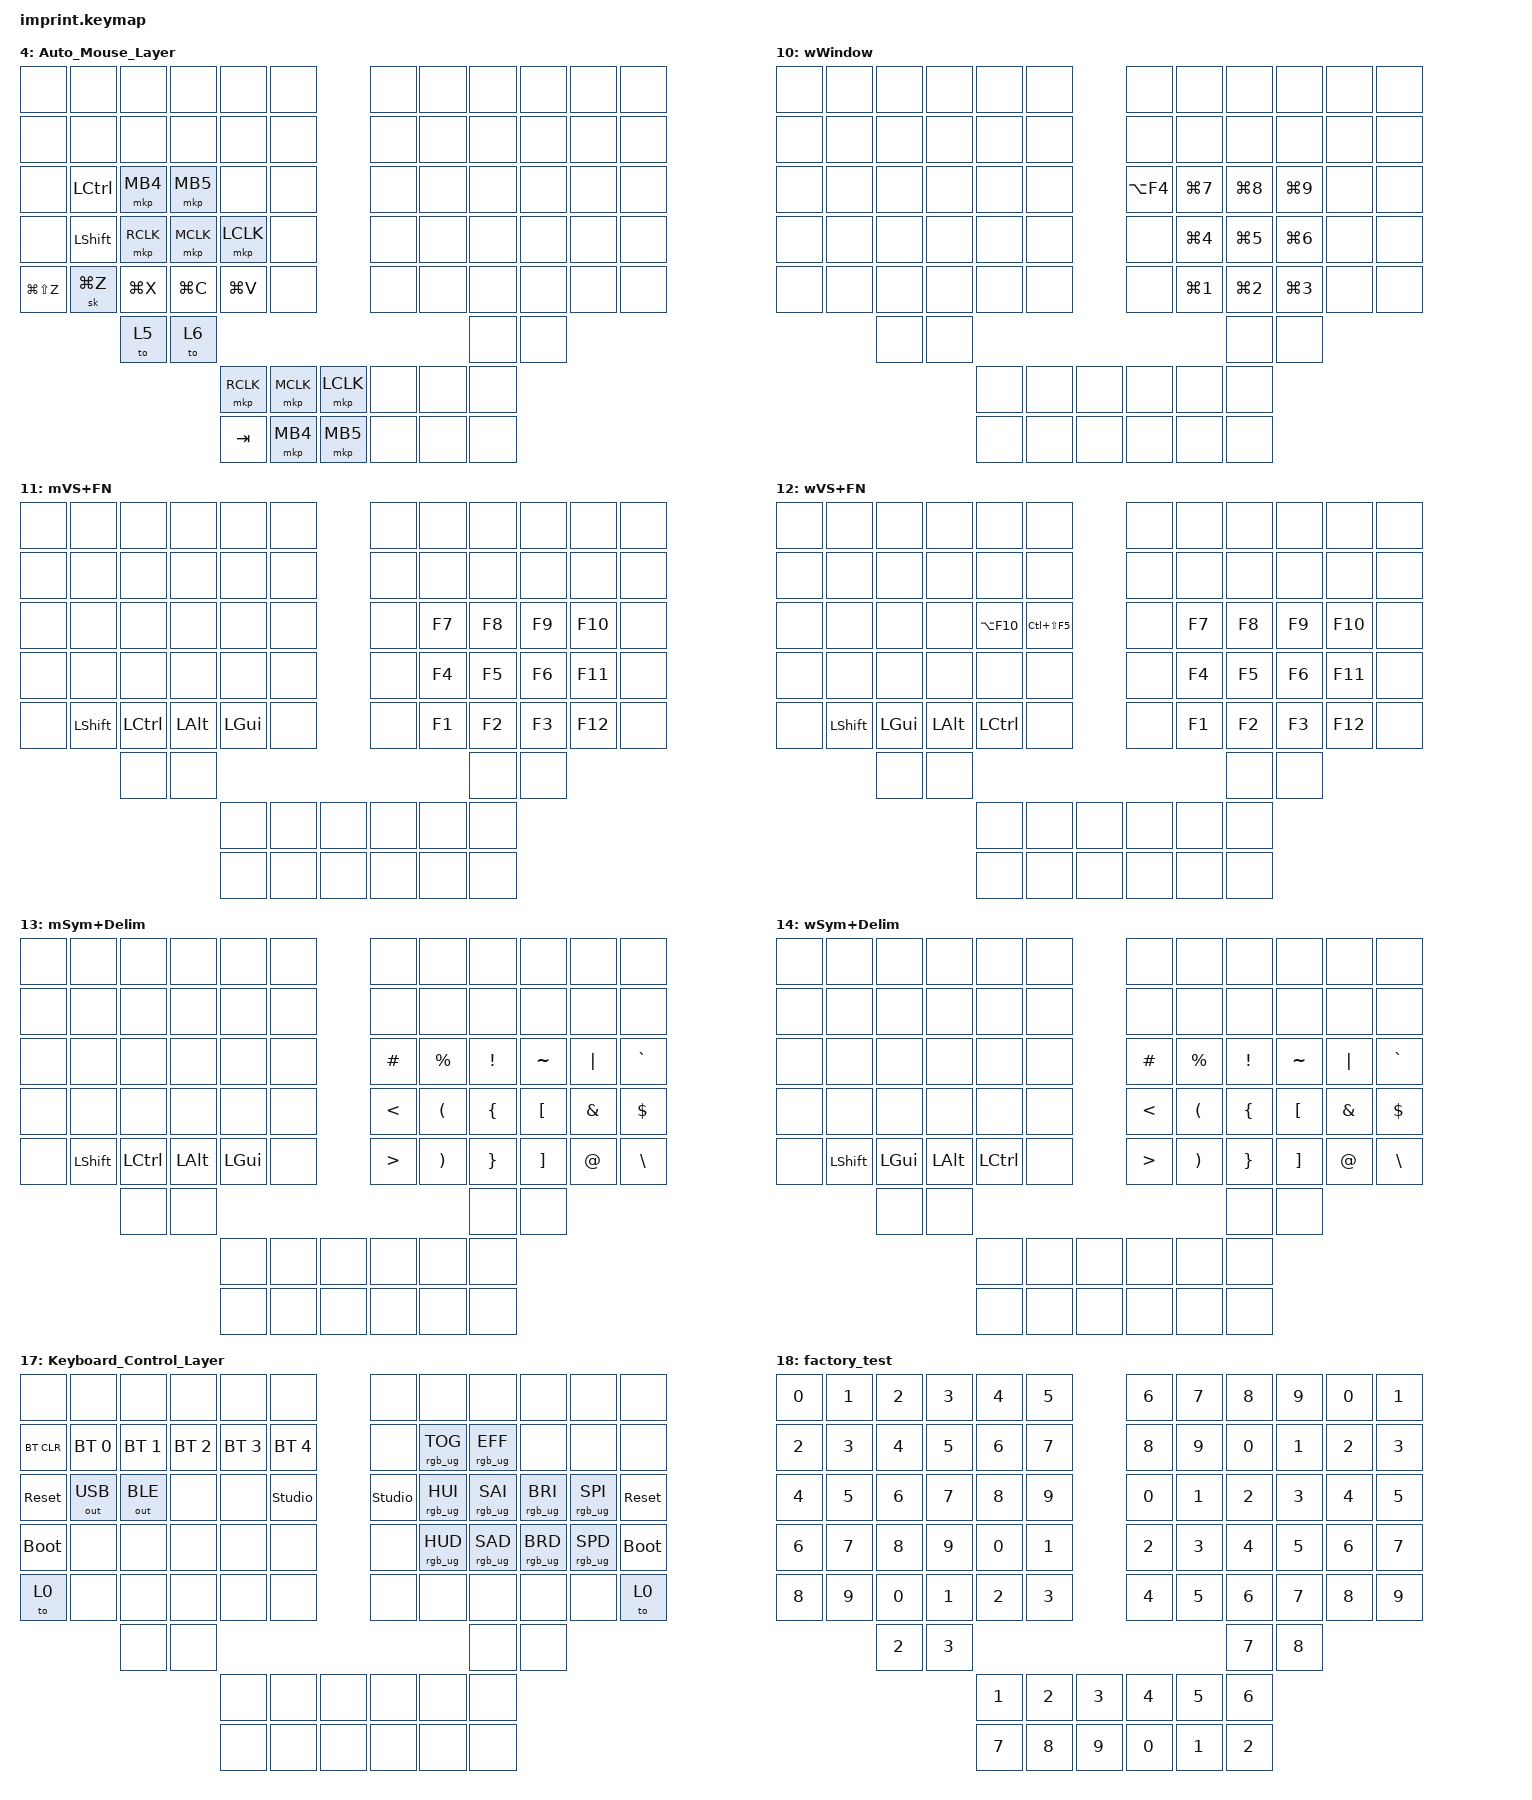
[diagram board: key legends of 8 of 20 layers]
#include <input/processors.dtsi>
#include <dt-bindings/zmk/input_transform.h>
#include <behaviors.dtsi>
#include <dt-bindings/zmk/bt.h>
#include <dt-bindings/zmk/keys.h>
#include <dt-bindings/zmk/outputs.h>
#include <dt-bindings/zmk/pointing.h>
#include <dt-bindings/zmk/rgb.h>

&mt {
    tapping-term-ms = <280>;
    quick-tap-ms = <175>;
    require-prior-idle-ms = <125>;
    flavor = "balanced";
};

&sk {
    quick-release;
    lazy;
};

/ {
    chosen { zmk,matrix-transform = &imprint_function_row; };

    combos {
        compatible = "zmk,combos";

        return {
            bindings = <&kp RET>;
            key-positions = <45 44 46>;
        };

        capsLock {
            bindings = <&kp CLCK>;
            key-positions = <56 57 51 50>;
        };

        tab {
            bindings = <&kp TAB>;
            key-positions = <43 44 45>;
        };

        backTab {
            bindings = <&kp LS(TAB)>;
            key-positions = <43 44 42>;
        };

        mHomeRowApp {
            bindings = <&kp LS(LA(LC(LG(F))))>;
            key-positions = <71 40>;
            layers = <0 2 7 9 11 13 15>;
        };

        lshift {
            bindings = <&kp LSHFT>;
            key-positions = <38 39>;
        };

        rshift {
            bindings = <&kp RSHIFT>;
            key-positions = <44 45>;
        };

        escape {
            bindings = <&kp ESCAPE>;
            key-positions = <43 44 45 46>;
        };

        mDelWord {
            bindings = <&kp LA(BACKSPACE)>;
            key-positions = <70 75>;
            layers = <0 2 7 9 11 13 15>;
        };

        StickyShift {
            bindings = <&sk LEFT_SHIFT>;
            key-positions = <71 74>;
        };

        To_MACOS {
            bindings = <&to_MAC_BASE>;
            key-positions = <36 37 38>;
        };

        to_mCSTR {
            bindings = <&to 2>;
            key-positions = <12 13 14>;
            layers = <0 2 7 9 11 13 15>;
        };

        to_SYS {
            bindings = <&to_SYS>;
            key-positions = <50 49 48>;
        };

        to_WINDOW {
            bindings = <&to_WINDOWS_BASE>;
            key-positions = <24 25 26>;
        };

        mLeaderKey {
            bindings = <&kp LS(LA(LC(RIGHT)))>;
            key-positions = <74 44>;
            layers = <0 2 7 9 11 13 15>;
        };

        caps_word {
            bindings = <&caps_word>;
            key-positions = <26 27 32 33>;
        };

        wDelWord {
            bindings = <&kp LC(BACKSPACE)>;
            key-positions = <75 70>;
        };

        to_wCSTR {
            bindings = <&to 3>;
            key-positions = <12 13 14>;
            layers = <1 3 8 10 12 14 16>;
        };

        goTo_MACOS {
            bindings = <&to_MACOS_OS>;
            key-positions = <13 22>;
        };

        goTo_WORK_WINDOW {
            bindings = <&to_WORK_WINDOW_OS>;
            key-positions = <17 18>;
        };

        sys_reset {
            bindings = <&sys_reset>;
            key-positions = <64 65 66>;
        };

        toggleRGB {
            bindings = <&rgb_ug RGB_TOG>;
            key-positions = <63 62>;
        };

        to_mGaming {
            bindings = <&to 19>;
            key-positions = <60 61 48 49>;
        };

        goTo_FUN_WINDOW {
            bindings = <&to_FUN_WINDOWS_OS>;
            key-positions = <16 19>;
        };

        goTo_IOS {
            bindings = <&to_IOS_OS>;
            key-positions = <14 21>;
        };

        goTo_IPADOS {
            bindings = <&to_IPADOS_OS>;
            key-positions = <15 20>;
        };
    };

    macros {
        wDelLine: wDelLine {
            compatible = "zmk,behavior-macro";
            #binding-cells = <0>;
            bindings = <&macro_tap>, <&kp END &kp LS(HOME) &kp BACKSPACE>;

            label = "WDELLINE";
        };

        mDelLine: mDelLine {
            compatible = "zmk,behavior-macro";
            #binding-cells = <0>;
            bindings = <&macro_tap>, <&kp LG(RIGHT) &kp LG(BACKSPACE)>;

            label = "MDELLINE";
        };

        wCtrlAltDel: wCtrlAltDel {
            compatible = "zmk,behavior-macro";
            #binding-cells = <0>;
            bindings = <&kp LA(LC(DEL))>;
            label = "WCTRLALTDEL";
        };

        to_MACOS_OS: toMACOS {
            compatible = "zmk,behavior-macro";
            #binding-cells = <0>;
            bindings = <&bt BT_SEL 0 &out OUT_BLE &to_MAC_BASE>;
            label = "TOMACOS";
        };

        to_WORK_WINDOW_OS: toWINDOW {
            compatible = "zmk,behavior-macro";
            #binding-cells = <0>;
            bindings = <&bt BT_SEL 4 &out OUT_BLE &to_WINDOWS_BASE>;
            label = "TOWINDOW";
        };

        calibrePressG: calibrePressG {
            compatible = "zmk,behavior-macro";
            #binding-cells = <0>;
            bindings =
                <&macro_wait_time 1>,
                <&kp LS(LA(LC(RIGHT))) &kp C>,
                <&macro_wait_time 100>,
                <&kp R &kp G>,
                <&macro_wait_time 1>,
                <&kp LS(LA(LC(RIGHT))) &kp O>;

            label = "CALIBREPRESSG";
        };

        to_SYS: to_SYS {
            compatible = "zmk,behavior-macro";
            #binding-cells = <0>;
            bindings = <&to 17 &rgb_ug RGB_COLOR_HSB(282,100,50)>;
            label = "TO_SYS";
        };

        to_WINDOWS_BASE: to_WINDOWS_BASE {
            compatible = "zmk,behavior-macro";
            #binding-cells = <0>;
            bindings = <&to 1 &rgb_ug RGB_COLOR_HSB(102,100,50)>;
            label = "TO_WINDOWS_BASE";
        };

        to_MAC_BASE: to_MAC_BASE {
            compatible = "zmk,behavior-macro";
            #binding-cells = <0>;
            bindings = <&to 0 &rgb_ug RGB_COLOR_HSB(21,100,50)>;
            label = "TO_MAC_BASE";
        };

        to_FUN_WINDOWS_OS: to_FUN_WINDOWS_OS {
            compatible = "zmk,behavior-macro";
            #binding-cells = <0>;
            bindings = <&bt BT_SEL 3 &out OUT_BLE &to_WINDOWS_BASE>;
            label = "TO_FUN_WINDOWS_OS";
        };

        to_IOS_OS: to_IOS {
            compatible = "zmk,behavior-macro";
            #binding-cells = <0>;
            bindings = <&bt BT_SEL 1 &out OUT_BLE &to_MAC_BASE>;
            label = "TO_IOS";
        };

        to_IPADOS_OS: to_IPADOS_OS {
            compatible = "zmk,behavior-macro";
            #binding-cells = <0>;
            bindings = <&bt BT_SEL 2 &out OUT_BLE &to_MAC_BASE>;
            label = "TO_IPADOS_OS";
        };

        mSwapLetters: swapLetters {
            compatible = "zmk,behavior-macro";
            #binding-cells = <0>;
            bindings = <&kp LS(RIGHT) &kp LG(X) &kp LEFT &kp LG(V)>;
            label = "SWAPLETTERS";
        };

        wSwapLetters: wSwapLetters {
            compatible = "zmk,behavior-macro";
            #binding-cells = <0>;
            bindings = <&kp LS(RIGHT) &kp LC(X) &kp LEFT &kp LC(V)>;
            label = "WSWAPLETTERS";
        };
    };

    keymap {
        compatible = "zmk,keymap";

        MAC_BASE {
            bindings = <
&none     &none             &none               &none           &none               &none                                                        &none                                &none                &none                &none                     &none                  &none
&none     &none             &none               &none           &none               &none                                                        &none                                &none                &none                &none                     &none                  &none
&kp ESC   &kp Q             &kp W               &kp E           &kp R               &kp T                                                        &kp Y                                &kp U                &kp I                &kp O                     &kp P                  &kp MINUS
&kp HASH  &kp A             &kp S               &kp D           &kp F               &kp G                                                        &kp H                                &kp J                &kp K                &kp L                     &kp SEMI               &kp SQT
&none     &mt LEFT_SHIFT Z  &mt LEFT_CONTROL X  &mt LEFT_ALT C  &mt LEFT_COMMAND V  &mt LG(LC(LS(LA(LEFT_COMMAND)))) B                           &mt RS(RA(RC(RG(RIGHT_COMMAND)))) N  &mt RIGHT_COMMAND M  &mt RIGHT_ALT COMMA  &mt RIGHT_CONTROL PERIOD  &mt RIGHT_SHIFT SLASH  &none
                            &to 5               &none                                                                                                                                                      &kp MINUS            &none
                                                                &lt 9 ESCAPE        &sk LEFT_SHIFT                      &kp LC(LS(LG(SPACE)))    &none                                &kp SPACE            &lt 11 DEL
                                                                &lt 15 TAB          &lt 7 E                             &kp RET                  &mSwapLetters                        &kp SPACE            &lt 13 BACKSPACE
            >;
        };

        WINDOW_BASE {
            bindings = <
&none    &none             &none           &none           &none               &none                                              &none                                &none                &none                &none                 &none                  &none
&none    &none             &none           &none           &none               &none                                              &none                                &none                &none                &none                 &none                  &none
&kp ESC  &kp Q             &kp W           &kp E           &kp R               &kp T                                              &kp Y                                &kp U                &kp I                &kp O                 &kp P                  &kp MINUS
&none    &kp A             &kp S           &kp D           &kp F               &kp G                                              &kp H                                &kp J                &kp K                &kp L                 &kp SEMI               &kp SQT
&none    &mt LEFT_SHIFT Z  &mt LEFT_GUI X  &mt LEFT_ALT C  &mt LEFT_CONTROL V  &mt LG(LC(LS(LA(LEFT_COMMAND)))) B                 &mt RS(RA(RC(RG(RIGHT_COMMAND)))) N  &mt RIGHT_CONTROL M  &mt RIGHT_ALT COMMA  &mt RIGHT_GUI PERIOD  &mt RIGHT_SHIFT SLASH  &none
                           &none           &to 6                                                                                                                                            &kp MINUS            &none
                                                           &lt 10 ESCAPE       &sk LEFT_SHIFT                      &kp LA(TAB)    &none                                &none                &lt 12 DEL
                                                           &lt 16 TAB          &lt 8 E                             &kp RET        &wSwapLetters                        &kp SPACE            &lt 14 BACKSPACE
            >;
        };

        mCSTR {
            bindings = <
&none     &none             &none               &none           &none               &none                                                                &none                                    &none                &none                &none                     &none              &none
&none     &none             &none               &none           &none               &none                                                                &none                                    &none                &none                &none                     &none              &none
&kp ESC   &kp B             &kp Y               &kp D           &kp L               &kp FSLH                                                             &kp Q                                    &kp F                &kp O                &kp U                     &kp Z              &kp EQUAL
&kp HASH  &kp C             &kp S               &kp T           &kp R               &kp J                                                                &kp K                                    &kp N                &kp A                &kp I                     &kp H              &kp SQT
&none     &mt LEFT_SHIFT V  &mt LEFT_CONTROL W  &mt LEFT_ALT G  &mt LEFT_COMMAND M  &mt LG(LC(LS(LA(LEFT_COMMAND)))) SEMICOLON                           &mt RS(RA(RC(RG(RIGHT_COMMAND)))) MINUS  &mt RIGHT_COMMAND P  &mt RIGHT_ALT COMMA  &mt RIGHT_CONTROL PERIOD  &mt RIGHT_SHIFT X  &none
                            &to 5               &none                                                                                                                                                                  &kp MINUS            &none
                                                                &lt 9 ESCAPE        &sk LEFT_SHIFT                              &kp LS(LA(LC(SPACE)))    &none                                    &sk LEFT_SHIFT       &lt 11 DEL
                                                                &lt 15 TAB          &lt 7 E                                     &kp RET                  &mSwapLetters                            &kp SPACE            &lt 13 BACKSPACE
            >;
        };

        wCSTR {
            bindings = <
&none    &none             &none           &none           &none               &none                                                  &none                                    &none                &none                &none                 &none              &none
&none    &none             &none           &none           &none               &none                                                  &none                                    &none                &none                &none                 &none              &none
&kp ESC  &kp B             &kp Y           &kp D           &kp L               &kp FSLH                                               &kp Q                                    &kp F                &kp O                &kp U                 &kp Z              &kp EQUAL
&none    &kp C             &kp S           &kp T           &kp R               &kp J                                                  &kp K                                    &kp N                &kp A                &kp I                 &kp H              &kp SQT
&none    &mt LEFT_SHIFT V  &mt LEFT_GUI W  &mt LEFT_ALT G  &mt LEFT_CONTROL M  &mt LG(LC(LS(LA(LEFT_COMMAND)))) SEMICOLON             &mt RS(RA(RC(RG(RIGHT_COMMAND)))) MINUS  &mt RIGHT_CONTROL P  &mt RIGHT_ALT COMMA  &mt RIGHT_GUI PERIOD  &mt RIGHT_SHIFT X  &none
                           &none           &none                                                                                                                                                    &kp MINUS            &none
                                                           &lt 10 ESCAPE       &none                                       &none      &none                                    &none                &lt 12 DEL
                                                           &lt 16 TAB          &lt 10 E                                    &kp RET    &wSwapLetters                            &kp SPACE            &lt 14 BACKSPACE
            >;
        };

        Auto_Mouse_Layer {
            bindings = <
&none          &none             &none      &none      &none      &none                   &none  &none  &none  &none  &none  &none
&none          &none             &none      &none      &none      &none                   &none  &none  &none  &none  &none  &none
&none          &kp LEFT_CONTROL  &mkp MB4   &mkp MB5   &none      &none                   &none  &none  &none  &none  &none  &none
&none          &kp LEFT_SHIFT    &mkp RCLK  &mkp MCLK  &mkp LCLK  &none                   &none  &none  &none  &none  &none  &none
&kp LG(LS(Z))  &sk LG(Z)         &kp LG(X)  &kp LG(C)  &kp LG(V)  &none                   &none  &none  &none  &none  &none  &none
                                 &to 5      &to 6                                                       &none  &none
                                                       &mkp RCLK  &mkp MCLK  &mkp LCLK    &none  &none  &none
                                                       &kp TAB    &mkp MB4   &mkp MB5     &none  &none  &none
            >;
        };

        mMouse {
            bindings = <
&none                         &none                      &none          &none      &none      &none                   &none  &none  &none  &none  &none  &none
&none                         &none                      &none          &none      &none      &none                   &none  &none  &none  &none  &none  &none
&kp LS(LC(LG(LA(B))))         &kp LS(LA(LC(LG(GRAVE))))  &mkp MB4       &mkp MB5   &kp LG(R)  &kp LG(X)               &none  &none  &none  &none  &none  &none
&kp LS(LA(LC(LG(NUMBER_4))))  &kp LS(LA(LC(LG(N2))))     &kp LS(LG(Z))  &kp LG(Z)  &kp LG(C)  &kp LG(V)               &none  &none  &none  &none  &none  &none
&kp LA(LS(LEFT_COMMAND))      &sk LEFT_SHIFT             &mkp RCLK      &mkp MCLK  &mkp LCLK  &kp ESC                 &none  &none  &none  &none  &none  &none
                                                         &to 0          &none                                                       &none  &none
                                                                                   &mkp RCLK  &mkp MCLK  &mkp LCLK    &none  &none  &none
                                                                                   &none      &mkp MB4   &mkp MB5     &none  &none  &none
            >;
        };

        wMouse {
            bindings = <
&none                     &none          &none          &none      &none      &none                                          &none  &none  &none  &none  &none  &none
&none                     &none          &none          &none      &none      &none                                          &none  &none  &none  &none  &none  &none
&none                     &none          &mkp MB4       &mkp MB5   &kp LC(R)  &kp LC(X)                                      &none  &none  &none  &none  &none  &none
&none                     &kp LS(LG(S))  &kp LS(LC(Z))  &kp LC(Z)  &kp LC(C)  &kp LC(V)                                      &none  &none  &none  &none  &none  &none
&kp LA(LS(LEFT_COMMAND))  &sk LSHFT      &mkp RCLK      &mkp MCLK  &mkp LCLK  &kp LC(LA(LS(LG(LEFT_CONTROL))))               &none  &none  &none  &none  &none  &none
                                         &none          &to 1                                                                              &none  &none
                                                                   &mkp RCLK  &mkp MCLK                         &mkp LCLK    &none  &none  &none
                                                                   &none      &mkp MB4                          &mkp MB5     &none  &none  &none
            >;
        };

        mShort+Nav {
            bindings = <
&none                         &none                      &none                 &none                  &none      &none               &none         &none      &none      &none          &none    &none
&none                         &none                      &none                 &none                  &none      &none               &none         &none      &none      &none          &none    &none
&kp LS(LC(LG(LA(B))))         &kp LS(LA(LC(LG(GRAVE))))  &kp LG(LEFT_BRACKET)  &kp LG(RIGHT_BRACKET)  &kp LG(R)  &kp LG(X)           &kp LS(TAB)   &kp PG_DN  &kp PG_UP  &kp TAB        &kp ESC  &none
&kp LS(LA(LC(LG(NUMBER_4))))  &kp LS(LA(LC(LG(N2))))     &kp LS(LG(Z))         &kp LG(Z)              &kp LG(C)  &kp LG(V)           &kp LEFT      &kp DOWN   &kp UP     &kp RIGHT      &kp RET  &none
&kp LA(LS(LEFT_COMMAND))      &kp LSHFT                  &kp LCTRL             &kp LALT               &kp LGUI   &kp ESC             &kp LG(LEFT)  &mDelLine  &none      &kp LG(RIGHT)  &none    &none
                                                         &none                 &none                                                                          &none      &none
                                                                                                      &none      &none      &none    &none         &none      &kp DEL
                                                                                                      &none      &none      &none    &none         &kp SPACE  &kp BSPC
            >;
        };

        wShort+Nav {
            bindings = <
&none                     &none             &none          &none          &none             &none                                      &none        &none      &none      &none      &none    &none
&none                     &none             &none          &none          &none             &none                                      &none        &none      &none      &none      &none    &none
&kp LA(N5)                &kp LA(GRAVE)     &kp LA(LEFT)   &kp LA(RIGHT)  &kp LC(R)         &kp LC(X)                                  &kp LS(TAB)  &kp PG_DN  &kp PG_UP  &kp TAB    &kp ESC  &none
&kp LA(NUMBER_2)          &kp LA(NUMBER_1)  &kp LS(LC(Z))  &kp LC(Z)      &kp LC(C)         &kp LC(V)                                  &kp LEFT     &kp DOWN   &kp UP     &kp RIGHT  &kp RET  &none
&kp LA(LS(LEFT_COMMAND))  &kp LSHFT         &kp LEFT_GUI   &kp LALT       &kp LEFT_CONTROL  &kp LC(LA(LS(LG(LEFT_CONTROL))))           &kp HOME     &wDelLine  &none      &kp END    &none    &none
                                            &none          &none                                                                                               &none      &none
                                                                          &wCtrlAltDel      &none                             &none    &none        &none      &kp DEL
                                                                          &none             &none                             &none    &none        &kp SPACE  &kp BSPC
            >;
        };

        mWindow {
            bindings = <
&none  &none                     &none                     &none                     &none                 &none                    &none                  &none                       &none                     &none          &none     &none
&none  &none                     &none                     &none                     &none                 &none                    &none                  &none                       &none                     &none          &none     &none
&none  &none                     &none                     &none                     &none                 &none                    &kp LA(LS(LC(SPACE)))  &kp N1                      &kp N2                    &kp N3         &kp N4    &kp LC(LA(LS(P)))
&none  &none                     &none                     &none                     &none                 &calibrePressG           &kp H                  &kp J                       &kp K                     &kp L          &kp SEMI  &kp SQT
&none  &sk LA(LC(LEFT_COMMAND))  &sk LS(LC(LEFT_COMMAND))  &sk LA(LS(LEFT_COMMAND))  &sk LS(LC(LEFT_ALT))  &none                    &kp LS(LC(LA(F)))      &kp LS(LA(LC(MINUS)))       &kp LS(LA(LC(EQUAL)))     &kp LG(LC(F))  &none     &kp LS(LC(LA(R)))
                                 &none                     &none                                                                                                                       &none                     &none
                                                                                     &none                 &none           &none    &none                  &none                       &none
                                                                                     &none                 &none           &none    &none                  &kp LS(LA(LC(LEFT_SHIFT)))  &kp LA(LC(LEFT_COMMAND))
            >;
        };

        wWindow {
            bindings = <
&none  &none  &none  &none  &none  &none           &none       &none       &none       &none       &none  &none
&none  &none  &none  &none  &none  &none           &none       &none       &none       &none       &none  &none
&none  &none  &none  &none  &none  &none           &kp LA(F4)  &kp LG(N7)  &kp LG(N8)  &kp LG(N9)  &none  &none
&none  &none  &none  &none  &none  &none           &none       &kp LG(N4)  &kp LG(N5)  &kp LG(N6)  &none  &none
&none  &none  &none  &none  &none  &none           &none       &kp LG(N1)  &kp LG(N2)  &kp LG(N3)  &none  &none
              &none  &none                                                 &none       &none
                            &none  &none  &none    &none       &none       &none
                            &none  &none  &none    &none       &none       &none
            >;
        };

        mVS+FN {
            bindings = <
&none  &none      &none      &none     &none     &none           &none  &none   &none   &none   &none    &none
&none  &none      &none      &none     &none     &none           &none  &none   &none   &none   &none    &none
&none  &none      &none      &none     &none     &none           &none  &kp F7  &kp F8  &kp F9  &kp F10  &none
&none  &none      &none      &none     &none     &none           &none  &kp F4  &kp F5  &kp F6  &kp F11  &none
&none  &kp LSHFT  &kp LCTRL  &kp LALT  &kp LGUI  &none           &none  &kp F1  &kp F2  &kp F3  &kp F12  &none
                  &none      &none                                              &none   &none
                                       &none     &none  &none    &none  &none   &none
                                       &none     &none  &none    &none  &none   &none
            >;
        };

        wVS+FN {
            bindings = <
&none  &none      &none         &none     &none             &none                    &none  &none   &none   &none   &none    &none
&none  &none      &none         &none     &none             &none                    &none  &none   &none   &none   &none    &none
&none  &none      &none         &none     &kp LA(F10)       &kp LC(LS(F5))           &none  &kp F7  &kp F8  &kp F9  &kp F10  &none
&none  &none      &none         &none     &none             &none                    &none  &kp F4  &kp F5  &kp F6  &kp F11  &none
&none  &kp LSHFT  &kp LEFT_GUI  &kp LALT  &kp LEFT_CONTROL  &none                    &none  &kp F1  &kp F2  &kp F3  &kp F12  &none
                  &none         &none                                                               &none   &none
                                          &none             &none           &none    &none  &none   &none
                                          &none             &none           &none    &none  &none   &none
            >;
        };

        mSym+Delim {
            bindings = <
&none  &none      &none      &none     &none     &none           &none             &none                  &none            &none              &none          &none
&none  &none      &none      &none     &none     &none           &none             &none                  &none            &none              &none          &none
&none  &none      &none      &none     &none     &none           &kp HASH          &kp PERCENT            &kp EXCLAMATION  &kp TILDE          &kp PIPE       &kp GRAVE
&none  &none      &none      &none     &none     &none           &kp LESS_THAN     &kp LEFT_PARENTHESIS   &kp LEFT_BRACE   &kp LEFT_BRACKET   &kp AMPERSAND  &kp DOLLAR
&none  &kp LSHFT  &kp LCTRL  &kp LALT  &kp LGUI  &none           &kp GREATER_THAN  &kp RIGHT_PARENTHESIS  &kp RIGHT_BRACE  &kp RIGHT_BRACKET  &kp AT_SIGN    &kp BACKSLASH
                  &none      &none                                                                        &none            &none
                                       &none     &none  &none    &none             &none                  &none
                                       &none     &none  &none    &none             &none                  &none
            >;
        };

        wSym+Delim {
            bindings = <
&none  &none      &none         &none     &none             &none           &none             &none                  &none            &none              &none          &none
&none  &none      &none         &none     &none             &none           &none             &none                  &none            &none              &none          &none
&none  &none      &none         &none     &none             &none           &kp HASH          &kp PERCENT            &kp EXCLAMATION  &kp TILDE          &kp PIPE       &kp GRAVE
&none  &none      &none         &none     &none             &none           &kp LESS_THAN     &kp LEFT_PARENTHESIS   &kp LEFT_BRACE   &kp LEFT_BRACKET   &kp AMPERSAND  &kp DOLLAR
&none  &kp LSHFT  &kp LEFT_GUI  &kp LALT  &kp LEFT_CONTROL  &none           &kp GREATER_THAN  &kp RIGHT_PARENTHESIS  &kp RIGHT_BRACE  &kp RIGHT_BRACKET  &kp AT_SIGN    &kp BACKSLASH
                  &none         &none                                                                                &none            &none
                                          &none             &none  &none    &none             &none                  &none
                                          &none             &none  &none    &none             &none                  &none
            >;
        };

        mMedia+Num {
            bindings = <
&none                         &none                     &none       &none              &none            &none                                      &none     &none   &none      &none   &none      &none
&none                         &none                     &none       &none              &none            &none                                      &none     &none   &none      &none   &none      &none
&none                         &kp C_BRIGHTNESS_MAXIMUM  &kp K_MUTE  &kp C_VOLUME_DOWN  &kp C_VOLUME_UP  &kp C_BRIGHTNESS_INC                       &kp STAR  &kp N7  &kp N8     &kp N9  &kp FSLH   &kp CARET
&none                         &kp C_BRIGHTNESS_MINIMUM  &kp C_PREV  &kp C_PP           &kp C_NEXT       &kp C_BRIGHTNESS_DEC                       &kp DOT   &kp N4  &kp N5     &kp N6  &kp EQUAL  &none
&kp LA(LS(LG(LEFT_COMMAND)))  &kp LSHFT                 &kp LCTRL   &kp LALT           &kp LGUI         &kp LG(LC(LA(LS(LEFT_COMMAND))))           &kp PLUS  &kp N1  &kp N2     &kp N3  &kp MINUS  &none
                                                        &none       &none                                                                                            &none      &none
                                                                                       &none            &none                             &none    &none     &none   &kp BSPC
                                                                                       &none            &none                             &none    &none     &kp N0  &kp SPACE
            >;
        };

        wMedia+Num {
            bindings = <
&none                         &none                     &none         &none              &none             &none                                      &none     &none   &none      &none   &none      &none
&none                         &none                     &none         &none              &none             &none                                      &none     &none   &none      &none   &none      &none
&none                         &kp C_BRIGHTNESS_MAXIMUM  &kp K_MUTE    &kp C_VOLUME_DOWN  &kp C_VOLUME_UP   &kp C_BRIGHTNESS_INC                       &kp STAR  &kp N7  &kp N8     &kp N9  &kp FSLH   &kp CARET
&none                         &kp C_BRIGHTNESS_MINIMUM  &kp C_PREV    &kp C_PLAY         &kp C_NEXT        &kp C_BRIGHTNESS_DEC                       &kp DOT   &kp N4  &kp N5     &kp N6  &kp EQUAL  &none
&kp LA(LS(LG(LEFT_COMMAND)))  &kp LSHFT                 &kp LEFT_GUI  &kp LALT           &kp LEFT_CONTROL  &kp LG(LC(LA(LS(LEFT_COMMAND))))           &kp PLUS  &kp N1  &kp N2     &kp N3  &kp MINUS  &none
                                                        &none         &none                                                                                             &none      &none
                                                                                         &none             &none                             &none    &none     &none   &kp BSPC
                                                                                         &none             &none                             &none    &none     &kp N0  &kp SPACE
            >;
        };

        Keyboard_Control_Layer {
            bindings = <
&none        &none         &none         &none         &none         &none                    &none           &none            &none            &none            &none            &none
&bt BT_CLR   &bt BT_SEL 0  &bt BT_SEL 1  &bt BT_SEL 2  &bt BT_SEL 3  &bt BT_SEL 4             &none           &rgb_ug RGB_TOG  &rgb_ug RGB_EFF  &none            &none            &none
&sys_reset   &out OUT_USB  &out OUT_BLE  &none         &none         &studio_unlock           &studio_unlock  &rgb_ug RGB_HUI  &rgb_ug RGB_SAI  &rgb_ug RGB_BRI  &rgb_ug RGB_SPI  &sys_reset
&bootloader  &none         &none         &none         &none         &none                    &none           &rgb_ug RGB_HUD  &rgb_ug RGB_SAD  &rgb_ug RGB_BRD  &rgb_ug RGB_SPD  &bootloader
&to 0        &none         &none         &none         &none         &none                    &none           &none            &none            &none            &none            &to 0
                           &none         &none                                                                                 &none            &none
                                                       &none         &none           &none    &none           &none            &none
                                                       &none         &none           &none    &none           &none            &none
            >;
        };

        factory_test {
            bindings = <
&kp N0  &kp N1  &kp N2  &kp N3  &kp N4  &kp N5            &kp N6  &kp N7  &kp N8  &kp N9  &kp N0  &kp N1
&kp N2  &kp N3  &kp N4  &kp N5  &kp N6  &kp N7            &kp N8  &kp N9  &kp N0  &kp N1  &kp N2  &kp N3
&kp N4  &kp N5  &kp N6  &kp N7  &kp N8  &kp N9            &kp N0  &kp N1  &kp N2  &kp N3  &kp N4  &kp N5
&kp N6  &kp N7  &kp N8  &kp N9  &kp N0  &kp N1            &kp N2  &kp N3  &kp N4  &kp N5  &kp N6  &kp N7
&kp N8  &kp N9  &kp N0  &kp N1  &kp N2  &kp N3            &kp N4  &kp N5  &kp N6  &kp N7  &kp N8  &kp N9
                &kp N2  &kp N3                                            &kp N7  &kp N8
                                &kp N1  &kp N2  &kp N3    &kp N4  &kp N5  &kp N6
                                &kp N7  &kp N8  &kp N9    &kp N0  &kp N1  &kp N2
            >;
        };

        mGAMING {
            bindings = <
&none    &none           &none         &none         &none      &none               &none                                &none                &none                &none                     &none                  &none
&none    &none           &kp NUMBER_1  &kp NUMBER_2  &none      &none               &none                                &none                &none                &none                     &none                  &none
&kp ESC  &kp Q           &kp A         &kp W         &kp R      &kp T               &kp Y                                &kp U                &kp I                &kp O                     &kp P                  &kp MINUS
&kp E    &kp LEFT_SHIFT  &kp D         &kp S         &kp F      &kp G               &kp H                                &kp J                &kp K                &kp L                     &kp SEMI               &kp SQT
&none    &kp Z           &kp X         &kp C         &kp V      &kp B               &mt RS(RA(RC(RG(RIGHT_COMMAND)))) N  &mt RIGHT_COMMAND M  &mt RIGHT_ALT COMMA  &mt RIGHT_CONTROL PERIOD  &mt RIGHT_SHIFT SLASH  &none
                         &none         &none                                                                                                  &kp MINUS            &none
                                                     &kp SPACE  &kp N9     &none    &none                                &kp SPACE            &lt 11 DEL
                                                     &kp TAB    &kp SPACE  &none    &none                                &kp SPACE            &lt 13 BACKSPACE
            >;
        };
    };
};

// right hand trackball configuration

&trackball_peripheral_listener {
    input-processors =
        //     activate layer 4 within 500ms of the trackball moving,,,,,,,,,,,,,,,,,,,,,,,,,,,,,,,,,,,,,,,,,,,,,,,,,,,,,,,,,,,,,,,,,,,,,,,,,,,,,,,,,,,,,,
        <&zip_temp_layer 4 500>;
};

// left hand trackball configuration

&trackball_central_listener {
    input-processors =
        // multiply sensitivity by 1, divide by 3 (make it slower for scrolling),,,,,,,,,,,,,,,,,,,,,,,,,,,,,,,,,,,,,,,,,,,,,,,,,,,,,,,,,,,,,,,,,,,,,,,,,,,,,,,,,,,,,,,,,,,,
        <&zip_xy_scaler 1 50>,
        // make this trackball output scrolling events by default instead of cursor movement,,,,,,,,,,,,,,,,,,,,,,,,,,,,,,,,,,,,,,,,,,,,,,,,,,,,,,,,,,,,,,,,,,,,,,,,,,,,,,,,,,,,,,,,,,,,
        <&zip_xy_to_scroll_mapper>,
        // invert vertical scrolling so that the view moves in the same direction as the top of the trackball.,,,,,,,,,,,,,,,,,,,,,,,,,,,,,,,,,,,,,,,,,,,,,,,,,,,,,,,,,,,,,,,,,,,,,,,,,,,,,,,,,,,,,,,,,,,,
        <&zip_scroll_transform INPUT_TRANSFORM_Y_INVERT>;
};
